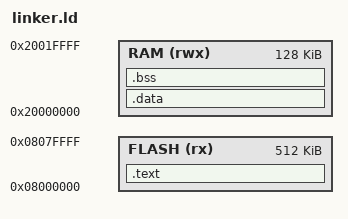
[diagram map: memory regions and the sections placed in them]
ENTRY(_start)

MEMORY
{
  FLASH (rx)  : ORIGIN = 0x08000000, LENGTH = 512K
  RAM (rwx)   : ORIGIN = 0x20000000, LENGTH = 128K
}

_estack = ORIGIN(RAM) + LENGTH(RAM);

SECTIONS
{
  .text :
  {
    KEEP(*(.isr_vector))
    *(.text*)
    *(.rodata*)
  } > FLASH

  .data : AT(__etext)
  {
    __data_start__ = .;
    *(.data*)
    __data_end__ = .;
  } > RAM

  .bss :
  {
    __bss_start__ = .;
    *(.bss*)
    *(COMMON)
    __bss_end__ = .;
  } > RAM

  __etext = LOADADDR(.data);
}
